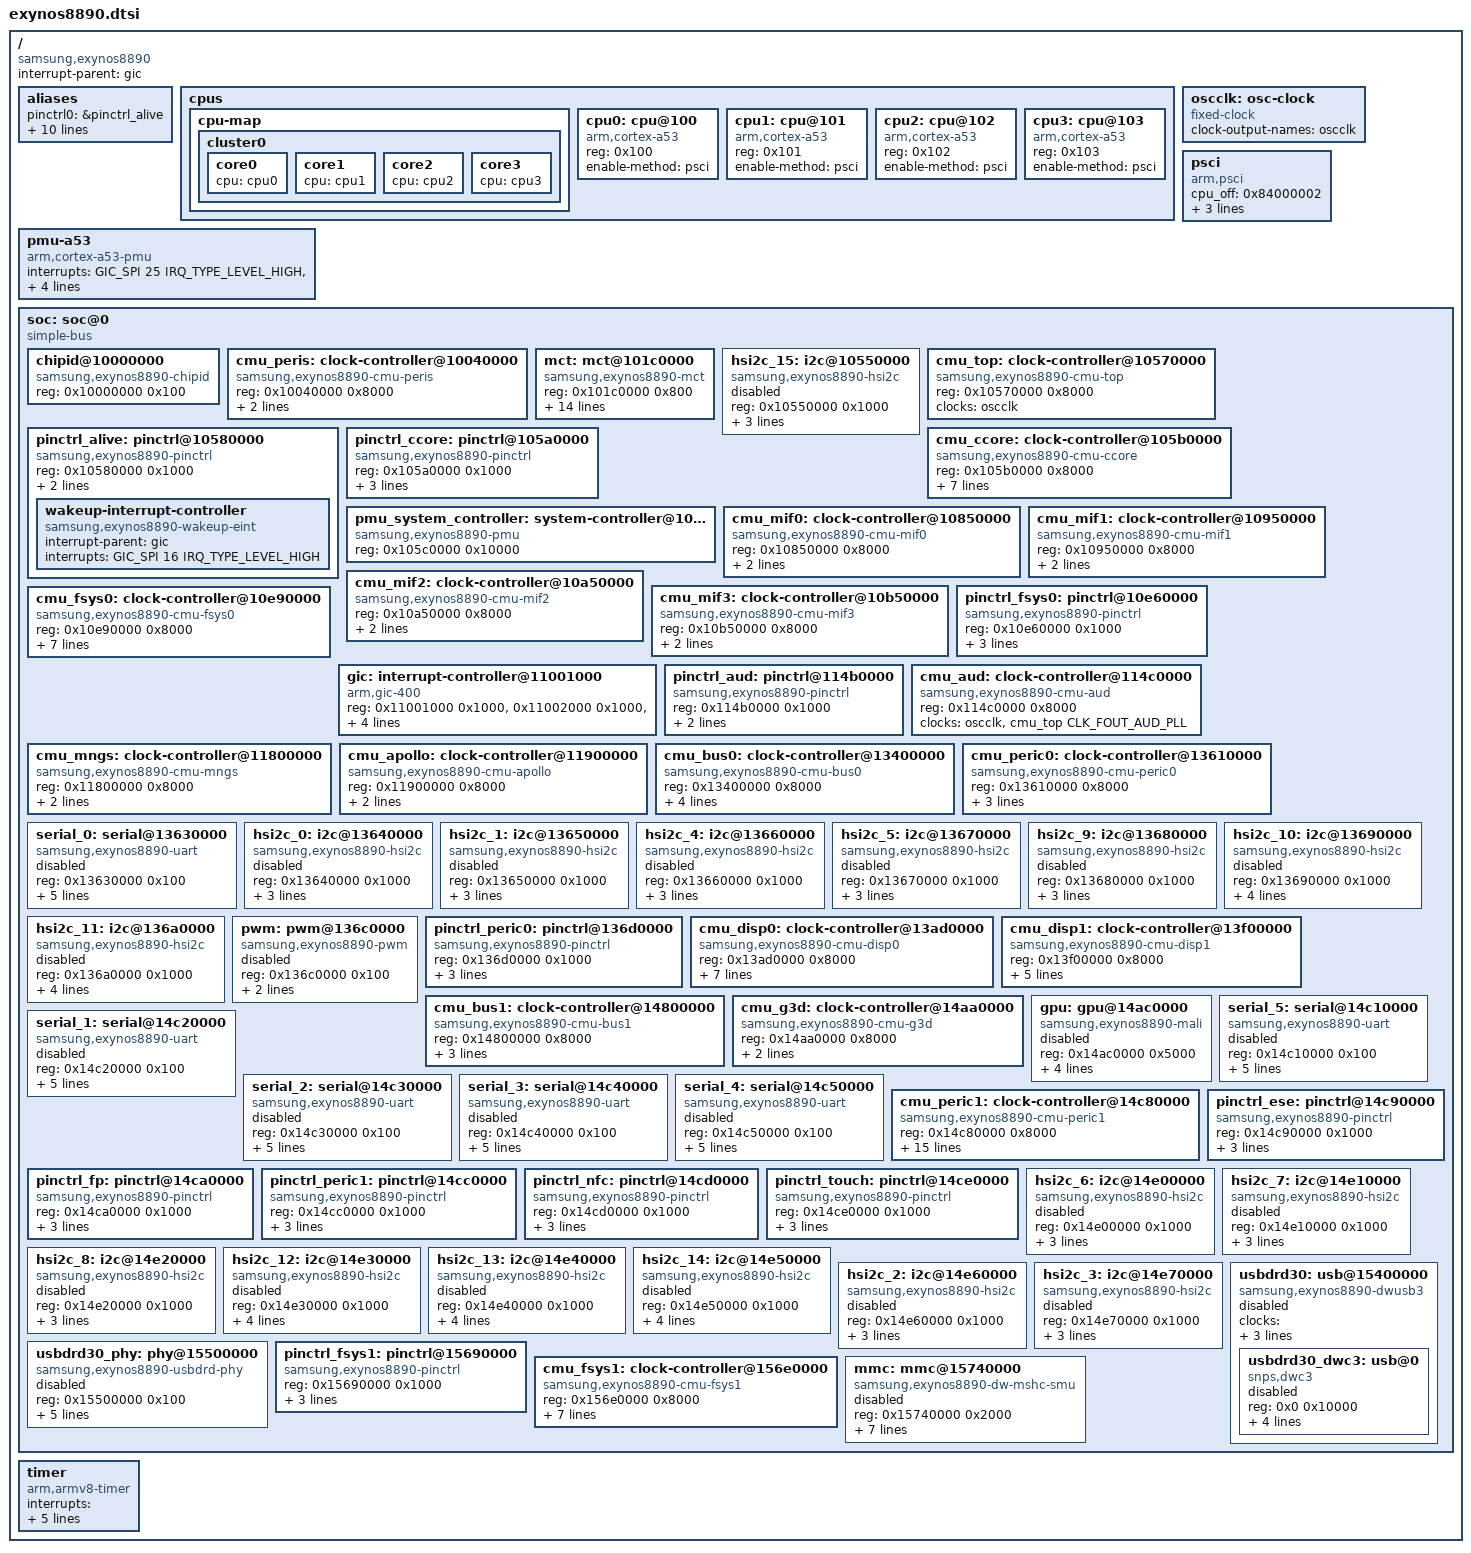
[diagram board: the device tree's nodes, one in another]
// SPDX-License-Identifier: GPL-2.0 OR BSD-3-Clause
/*
 * Samsung Exynos 8890 SoC device tree source
 *
 * Copyright (c) 2025 Ivaylo Ivanov <ivo.ivanov.ivanov1@gmail.com>
 */

#include <dt-bindings/clock/samsung,exynos8890-cmu.h>
#include <dt-bindings/interrupt-controller/arm-gic.h>

/ {
	compatible = "samsung,exynos8890";
	#address-cells = <2>;
	#size-cells = <1>;

	interrupt-parent = <&gic>;

	aliases {
		pinctrl0 = &pinctrl_alive;
		pinctrl1 = &pinctrl_aud;
		pinctrl2 = &pinctrl_ccore;
		pinctrl3 = &pinctrl_fp;
		pinctrl4 = &pinctrl_ese;
		pinctrl5 = &pinctrl_fsys0;
		pinctrl6 = &pinctrl_fsys1;
		pinctrl7 = &pinctrl_nfc;
		pinctrl8 = &pinctrl_peric0;
		pinctrl9 = &pinctrl_peric1;
		pinctrl10 = &pinctrl_touch;
	};

	cpus {
		#address-cells = <1>;
		#size-cells = <0>;

		cpu-map {
			cluster0 {
				core0 {
					cpu = <&cpu0>;
				};
				core1 {
					cpu = <&cpu1>;
				};
				core2 {
					cpu = <&cpu2>;
				};
				core3 {
					cpu = <&cpu3>;
				};
			};
		};

		/*
		 * The Mongoose M1 cores have an errata, where memory accesses
		 * to certain virtual addresses can trigger a TLB conflict abort,
		 * even when running Linux in EL2.
		 */

		cpu0: cpu@100 {
			device_type = "cpu";
			compatible = "arm,cortex-a53";
			reg = <0x100>;
			enable-method = "psci";
		};

		cpu1: cpu@101 {
			device_type = "cpu";
			compatible = "arm,cortex-a53";
			reg = <0x101>;
			enable-method = "psci";
		};

		cpu2: cpu@102 {
			device_type = "cpu";
			compatible = "arm,cortex-a53";
			reg = <0x102>;
			enable-method = "psci";
		};

		cpu3: cpu@103 {
			device_type = "cpu";
			compatible = "arm,cortex-a53";
			reg = <0x103>;
			enable-method = "psci";
		};
	};

	oscclk: osc-clock {
		compatible = "fixed-clock";
		#clock-cells = <0>;
		clock-output-names = "oscclk";
	};

	pmu-a53 {
		compatible = "arm,cortex-a53-pmu";
		interrupts = <GIC_SPI 25 IRQ_TYPE_LEVEL_HIGH>,
			     <GIC_SPI 26 IRQ_TYPE_LEVEL_HIGH>,
			     <GIC_SPI 27 IRQ_TYPE_LEVEL_HIGH>,
			     <GIC_SPI 28 IRQ_TYPE_LEVEL_HIGH>;
		interrupt-affinity = <&cpu0>,
				     <&cpu1>,
				     <&cpu2>,
				     <&cpu3>;
	};

	psci {
		compatible = "arm,psci";
		cpu_off = <0x84000002>;
		cpu_on = <0xc4000003>;
		cpu_suspend = <0xc4000001>;
		method = "smc";
	};

	soc: soc@0 {
		compatible = "simple-bus";
		ranges = <0x0 0x0 0x0 0x20000000>;

		#address-cells = <1>;
		#size-cells = <1>;

		chipid@10000000 {
			compatible = "samsung,exynos8890-chipid",
				     "samsung,exynos4210-chipid";
			reg = <0x10000000 0x100>;
		};

		cmu_peris: clock-controller@10040000 {
			compatible = "samsung,exynos8890-cmu-peris";
			reg = <0x10040000 0x8000>;
			#clock-cells = <1>;
			clocks = <&oscclk>,
				 <&cmu_top CLK_GOUT_TOP_ACLK_PERIS_66>;
			clock-names = "oscclk", "peris";
		};

		mct: mct@101c0000 {
			compatible = "samsung,exynos8890-mct",
				     "samsung,exynos4210-mct";
			reg = <0x101c0000 0x800>;

			clocks = <&oscclk>, <&cmu_peris CLK_GOUT_PERIS_PCLK_MCT>;
			clock-names = "fin_pll", "mct";

			interrupts = <GIC_SPI 81 IRQ_TYPE_LEVEL_HIGH>,
				     <GIC_SPI 82 IRQ_TYPE_LEVEL_HIGH>,
				     <GIC_SPI 83 IRQ_TYPE_LEVEL_HIGH>,
				     <GIC_SPI 84 IRQ_TYPE_LEVEL_HIGH>,
				     <GIC_SPI 85 IRQ_TYPE_LEVEL_HIGH>,
				     <GIC_SPI 86 IRQ_TYPE_LEVEL_HIGH>,
				     <GIC_SPI 87 IRQ_TYPE_LEVEL_HIGH>,
				     <GIC_SPI 88 IRQ_TYPE_LEVEL_HIGH>,
				     <GIC_SPI 89 IRQ_TYPE_LEVEL_HIGH>,
				     <GIC_SPI 90 IRQ_TYPE_LEVEL_HIGH>,
				     <GIC_SPI 91 IRQ_TYPE_LEVEL_HIGH>,
				     <GIC_SPI 92 IRQ_TYPE_LEVEL_HIGH>;
		};

		hsi2c_15: i2c@10550000 {
			compatible = "samsung,exynos8890-hsi2c",
				     "samsung,exynos8895-hsi2c";
			reg = <0x10550000 0x1000>;

			clocks = <&cmu_ccore CLK_GOUT_CCORE_PCLK_HSI2C>;
			clock-names = "hsi2c";

			interrupts = <GIC_SPI 340 IRQ_TYPE_LEVEL_HIGH>;

			pinctrl-0 = <&hsi2c15_bus>;
			pinctrl-names = "default";

			#address-cells = <1>;
			#size-cells = <0>;

			status = "disabled";
		};

		cmu_top: clock-controller@10570000 {
			compatible = "samsung,exynos8890-cmu-top";
			reg = <0x10570000 0x8000>;
			#clock-cells = <1>;
			clocks = <&oscclk>;
			clock-names = "oscclk";
		};

		pinctrl_alive: pinctrl@10580000 {
			compatible = "samsung,exynos8890-pinctrl";
			reg = <0x10580000 0x1000>;
			clocks = <&cmu_ccore CLK_GOUT_CCORE_PCLK_GPIO_APBIF_ALIVE>;
			clock-names = "pclk";

			wakeup-interrupt-controller {
				compatible = "samsung,exynos8890-wakeup-eint",
					     "samsung,exynos7-wakeup-eint";
				interrupt-parent = <&gic>;
				interrupts = <GIC_SPI 16 IRQ_TYPE_LEVEL_HIGH>;
			};
		};

		pinctrl_ccore: pinctrl@105a0000 {
			compatible = "samsung,exynos8890-pinctrl";
			reg = <0x105a0000 0x1000>;
			interrupts = <GIC_SPI 383 IRQ_TYPE_LEVEL_HIGH>;
			clocks = <&cmu_ccore CLK_GOUT_CCORE_PCLK_GPIO_CCORE>;
			clock-names = "pclk";
		};

		cmu_ccore: clock-controller@105b0000 {
			compatible = "samsung,exynos8890-cmu-ccore";
			reg = <0x105b0000 0x8000>;
			#clock-cells = <1>;
			clocks = <&oscclk>,
				 <&cmu_top CLK_GOUT_TOP_ACLK_CCORE_800>,
				 <&cmu_top CLK_GOUT_TOP_ACLK_CCORE_264>,
				 <&cmu_top CLK_GOUT_TOP_ACLK_CCORE_G3D_800>,
				 <&cmu_top CLK_GOUT_TOP_ACLK_CCORE_528>,
				 <&cmu_top CLK_GOUT_TOP_ACLK_CCORE_132>,
				 <&cmu_top CLK_GOUT_TOP_PCLK_CCORE_66>;
			clock-names = "oscclk", "800", "264", "g3d", "528",
				      "132", "66";
		};

		pmu_system_controller: system-controller@105c0000 {
			compatible = "samsung,exynos8890-pmu",
				     "samsung,exynos7-pmu", "syscon";
			reg = <0x105c0000 0x10000>;
		};

		cmu_mif0: clock-controller@10850000 {
			compatible = "samsung,exynos8890-cmu-mif0";
			reg = <0x10850000 0x8000>;
			#clock-cells = <1>;
			clocks = <&oscclk>,
				 <&cmu_top CLK_GOUT_TOP_SCLK_BUS_PLL_MIF>;
			clock-names = "oscclk", "bus";
		};

		cmu_mif1: clock-controller@10950000 {
			compatible = "samsung,exynos8890-cmu-mif1";
			reg = <0x10950000 0x8000>;
			#clock-cells = <1>;
			clocks = <&oscclk>,
				 <&cmu_top CLK_GOUT_TOP_SCLK_BUS_PLL_MIF>;
			clock-names = "oscclk", "bus";
		};

		cmu_mif2: clock-controller@10a50000 {
			compatible = "samsung,exynos8890-cmu-mif2";
			reg = <0x10a50000 0x8000>;
			#clock-cells = <1>;
			clocks = <&oscclk>,
				 <&cmu_top CLK_GOUT_TOP_SCLK_BUS_PLL_MIF>;
			clock-names = "oscclk", "bus";
		};

		cmu_mif3: clock-controller@10b50000 {
			compatible = "samsung,exynos8890-cmu-mif3";
			reg = <0x10b50000 0x8000>;
			#clock-cells = <1>;
			clocks = <&oscclk>,
				 <&cmu_top CLK_GOUT_TOP_SCLK_BUS_PLL_MIF>;
			clock-names = "oscclk", "bus";
		};

		pinctrl_fsys0: pinctrl@10e60000 {
			compatible = "samsung,exynos8890-pinctrl";
			reg = <0x10e60000 0x1000>;
			clocks = <&cmu_fsys0 CLK_GOUT_FSYS0_PCLK_GPIO_FSYS0>;
			clock-names = "pclk";
			interrupts = <GIC_SPI 212 IRQ_TYPE_LEVEL_HIGH>;
		};

		cmu_fsys0: clock-controller@10e90000 {
			compatible = "samsung,exynos8890-cmu-fsys0";
			reg = <0x10e90000 0x8000>;
			#clock-cells = <1>;
			clocks = <&oscclk>,
				 <&cmu_top CLK_GOUT_TOP_ACLK_FSYS0_200>,
				 <&cmu_top CLK_GOUT_TOP_SCLK_FSYS0_USBDRD30>,
				 <&cmu_top CLK_GOUT_TOP_SCLK_FSYS0_MMC0>,
				 <&cmu_top CLK_GOUT_TOP_SCLK_FSYS0_UFSUNIPRO20>,
				 <&cmu_top CLK_GOUT_TOP_SCLK_FSYS0_PHY_24M>,
				 <&cmu_top CLK_GOUT_TOP_SCLK_FSYS0_UFSUNIPRO_CFG>;
			clock-names = "oscclk", "200", "usb", "mmc", "unipro20",
				      "24m", "unipro_cfg";
		};

		gic: interrupt-controller@11001000 {
			compatible = "arm,gic-400";
			reg = <0x11001000 0x1000>,
			      <0x11002000 0x1000>,
			      <0x11004000 0x2000>,
			      <0x11006000 0x2000>;
			#interrupt-cells = <3>;
			interrupt-controller;
			interrupts = <GIC_PPI 9 (GIC_CPU_MASK_SIMPLE(8) |
						 IRQ_TYPE_LEVEL_HIGH)>;
			#address-cells = <0>;
			#size-cells = <1>;
		};

		pinctrl_aud: pinctrl@114b0000 {
			compatible = "samsung,exynos8890-pinctrl";
			reg = <0x114b0000 0x1000>;
			clocks = <&cmu_aud CLK_GOUT_AUD_PCLK_GPIO_AUD>;
			clock-names = "pclk";
			interrupts = <GIC_SPI 61 IRQ_TYPE_LEVEL_HIGH>;
		};

		cmu_aud: clock-controller@114c0000 {
			compatible = "samsung,exynos8890-cmu-aud";
			reg = <0x114c0000 0x8000>;
			#clock-cells = <1>;
			clocks = <&oscclk>,
				 <&cmu_top CLK_FOUT_AUD_PLL>;
			clock-names = "oscclk", "pll";
		};

		cmu_mngs: clock-controller@11800000 {
			compatible = "samsung,exynos8890-cmu-mngs";
			reg = <0x11800000 0x8000>;
			#clock-cells = <1>;
			clocks = <&oscclk>,
				 <&cmu_top CLK_GOUT_TOP_SCLK_BUS_PLL_MNGS>;
			clock-names = "oscclk", "bus";
		};

		cmu_apollo: clock-controller@11900000 {
			compatible = "samsung,exynos8890-cmu-apollo";
			reg = <0x11900000 0x8000>;
			#clock-cells = <1>;
			clocks = <&oscclk>,
				 <&cmu_top CLK_GOUT_TOP_SCLK_BUS_PLL_APOLLO>;
			clock-names = "oscclk", "bus";
		};

		cmu_bus0: clock-controller@13400000 {
			compatible = "samsung,exynos8890-cmu-bus0";
			reg = <0x13400000 0x8000>;
			#clock-cells = <1>;
			clocks = <&oscclk>,
				 <&cmu_top CLK_GOUT_TOP_ACLK_BUS0_528>,
				 <&cmu_top CLK_GOUT_TOP_ACLK_BUS0_200>,
				 <&cmu_top CLK_GOUT_TOP_PCLK_BUS0_132>;
			clock-names = "oscclk", "528", "200", "132";
		};

		cmu_peric0: clock-controller@13610000 {
			compatible = "samsung,exynos8890-cmu-peric0";
			reg = <0x13610000 0x8000>;
			#clock-cells = <1>;
			clocks = <&oscclk>,
				 <&cmu_top CLK_GOUT_TOP_ACLK_PERIC0_66>,
				 <&cmu_top CLK_GOUT_TOP_SCLK_PERIC0_UART0>;
			clock-names = "oscclk", "66", "uart0";
		};

		serial_0: serial@13630000 {
			compatible = "samsung,exynos8890-uart",
				     "samsung,exynos8895-uart";
			reg = <0x13630000 0x100>;

			clocks = <&cmu_peric0 CLK_GOUT_PERIC0_PCLK_UART0>,
				 <&cmu_peric0 CLK_GOUT_PERIC0_SCLK_UART0>;
			clock-names = "uart", "clk_uart_baud0";

			interrupts = <GIC_SPI 429 IRQ_TYPE_LEVEL_HIGH>;

			pinctrl-0 = <&uart0_bus>;
			pinctrl-names = "default";

			samsung,uart-fifosize = <256>;

			status = "disabled";
		};

		hsi2c_0: i2c@13640000 {
			compatible = "samsung,exynos8890-hsi2c",
				     "samsung,exynos8895-hsi2c";
			reg = <0x13640000 0x1000>;

			clocks = <&cmu_peric0 CLK_GOUT_PERIC0_PCLK_HSI2C0>;
			clock-names = "hsi2c";

			interrupts = <GIC_SPI 416 IRQ_TYPE_LEVEL_HIGH>;

			pinctrl-0 = <&hsi2c0_bus>;
			pinctrl-names = "default";

			#address-cells = <1>;
			#size-cells = <0>;

			status = "disabled";
		};

		hsi2c_1: i2c@13650000 {
			compatible = "samsung,exynos8890-hsi2c",
				     "samsung,exynos8895-hsi2c";
			reg = <0x13650000 0x1000>;

			clocks = <&cmu_peric0 CLK_GOUT_PERIC0_PCLK_HSI2C1>;
			clock-names = "hsi2c";

			interrupts = <GIC_SPI 417 IRQ_TYPE_LEVEL_HIGH>;

			pinctrl-0 = <&hsi2c1_bus>;
			pinctrl-names = "default";

			#address-cells = <1>;
			#size-cells = <0>;

			status = "disabled";
		};

		hsi2c_4: i2c@13660000 {
			compatible = "samsung,exynos8890-hsi2c",
				     "samsung,exynos8895-hsi2c";
			reg = <0x13660000 0x1000>;

			clocks = <&cmu_peric0 CLK_GOUT_PERIC0_PCLK_HSI2C4>;
			clock-names = "hsi2c";

			interrupts = <GIC_SPI 418 IRQ_TYPE_LEVEL_HIGH>;

			pinctrl-0 = <&hsi2c4_bus>;
			pinctrl-names = "default";

			#address-cells = <1>;
			#size-cells = <0>;

			status = "disabled";
		};

		hsi2c_5: i2c@13670000 {
			compatible = "samsung,exynos8890-hsi2c",
				     "samsung,exynos8895-hsi2c";
			reg = <0x13670000 0x1000>;

			clocks = <&cmu_peric0 CLK_GOUT_PERIC0_PCLK_HSI2C5>;
			clock-names = "hsi2c";

			interrupts = <GIC_SPI 419 IRQ_TYPE_LEVEL_HIGH>;

			pinctrl-0 = <&hsi2c5_bus>;
			pinctrl-names = "default";

			#address-cells = <1>;
			#size-cells = <0>;

			status = "disabled";
		};

		hsi2c_9: i2c@13680000 {
			compatible = "samsung,exynos8890-hsi2c",
				     "samsung,exynos8895-hsi2c";
			reg = <0x13680000 0x1000>;

			clocks = <&cmu_peric0 CLK_GOUT_PERIC0_PCLK_HSI2C9>;
			clock-names = "hsi2c";

			interrupts = <GIC_SPI 420 IRQ_TYPE_LEVEL_HIGH>;

			pinctrl-0 = <&hsi2c9_bus>;
			pinctrl-names = "default";

			#address-cells = <1>;
			#size-cells = <0>;

			status = "disabled";
		};

		hsi2c_10: i2c@13690000 {
			compatible = "samsung,exynos8890-hsi2c",
				     "samsung,exynos8895-hsi2c";
			reg = <0x13690000 0x1000>;

			clocks = <&cmu_peric0 CLK_GOUT_PERIC0_PCLK_HSI2C10>;
			clock-names = "hsi2c";

			interrupts = <GIC_SPI 421 IRQ_TYPE_LEVEL_HIGH>;

			pinctrl-0 = <&hsi2c10_bus>;
			pinctrl-names = "default";

			#address-cells = <1>;
			#size-cells = <0>;

			status = "disabled";
		};

		hsi2c_11: i2c@136a0000 {
			compatible = "samsung,exynos8890-hsi2c",
				     "samsung,exynos8895-hsi2c";
			reg = <0x136a0000 0x1000>;

			clocks = <&cmu_peric0 CLK_GOUT_PERIC0_PCLK_HSI2C11>;
			clock-names = "hsi2c";

			interrupts = <GIC_SPI 422 IRQ_TYPE_LEVEL_HIGH>;

			pinctrl-0 = <&hsi2c11_bus>;
			pinctrl-names = "default";

			#address-cells = <1>;
			#size-cells = <0>;

			status = "disabled";
		};

		pwm: pwm@136c0000 {
			compatible = "samsung,exynos8890-pwm",
				     "samsung,exynos4210-pwm";
			reg = <0x136c0000 0x100>;
			clocks = <&cmu_peric0 CLK_GOUT_PERIC0_PCLK_PWM>;
			clock-names = "timers";
			#pwm-cells = <3>;
			samsung,pwm-outputs = <0>, <1>, <2>, <3>;
			status = "disabled";
		};

		pinctrl_peric0: pinctrl@136d0000 {
			compatible = "samsung,exynos8890-pinctrl";
			reg = <0x136d0000 0x1000>;
			interrupts = <GIC_SPI 430 IRQ_TYPE_LEVEL_HIGH>;
			clocks = <&cmu_peric0 CLK_GOUT_PERIC0_PCLK_GPIO_BUS0>;
			clock-names = "pclk";
		};

		cmu_disp0: clock-controller@13ad0000 {
			compatible = "samsung,exynos8890-cmu-disp0";
			reg = <0x13ad0000 0x8000>;
			#clock-cells = <1>;
			clocks = <&oscclk>,
				 <&cmu_top CLK_GOUT_TOP_ACLK_DISP0_0_400>,
				 <&cmu_top CLK_GOUT_TOP_ACLK_DISP0_1_400>,
				 <&cmu_top CLK_GOUT_TOP_SCLK_DISP0_DECON0_ECLK0>,
				 <&cmu_top CLK_GOUT_TOP_SCLK_DISP0_DECON0_VCLK0>,
				 <&cmu_top CLK_GOUT_TOP_SCLK_DISP0_DECON0_VCLK1>,
				 <&cmu_top CLK_GOUT_TOP_SCLK_DISP0_HDMI_AUDIO>;
			clock-names = "oscclk", "0_400", "1_400", "eclk0",
				      "vclk0", "vclk1", "audio";
		};

		cmu_disp1: clock-controller@13f00000 {
			compatible = "samsung,exynos8890-cmu-disp1";
			reg = <0x13f00000 0x8000>;
			#clock-cells = <1>;
			clocks = <&oscclk>,
				 <&cmu_top CLK_GOUT_TOP_ACLK_DISP1_0_400>,
				 <&cmu_top CLK_GOUT_TOP_ACLK_DISP1_1_400>,
				 <&cmu_top CLK_GOUT_TOP_SCLK_DISP1_DECON1_ECLK0>,
				 <&cmu_top CLK_GOUT_TOP_SCLK_DISP1_DECON1_ECLK1>;
			clock-names = "oscclk", "0_400", "1_400", "eclk0",
				      "eclk01";
		};

		cmu_bus1: clock-controller@14800000 {
			compatible = "samsung,exynos8890-cmu-bus1";
			reg = <0x14800000 0x8000>;
			#clock-cells = <1>;
			clocks = <&oscclk>,
				 <&cmu_top CLK_GOUT_TOP_ACLK_BUS0_528>,
				 <&cmu_top CLK_GOUT_TOP_PCLK_BUS1_132>;
			clock-names = "oscclk", "528", "132";
		};

		cmu_g3d: clock-controller@14aa0000 {
			compatible = "samsung,exynos8890-cmu-g3d";
			reg = <0x14aa0000 0x8000>;
			#clock-cells = <1>;
			clocks = <&oscclk>,
				 <&cmu_top CLK_FOUT_G3D_PLL>,
				 <&cmu_top CLK_GOUT_TOP_SCLK_BUS_PLL_G3D>;
			clock-names = "oscclk", "pll", "bus";
		};

		gpu: gpu@14ac0000 {
			compatible = "samsung,exynos8890-mali", "arm,mali-t880";
			reg = <0x14ac0000 0x5000>;

			clocks = <&cmu_g3d CLK_GOUT_G3D_ACLK_G3D>;
			clock-names = "core";

			interrupts = <GIC_SPI 225 IRQ_TYPE_LEVEL_HIGH>,
				     <GIC_SPI 226 IRQ_TYPE_LEVEL_HIGH>,
				     <GIC_SPI 224 IRQ_TYPE_LEVEL_HIGH>;
			interrupt-names = "job", "mmu", "gpu";

			status = "disabled";
		};

		serial_5: serial@14c10000 {
			compatible = "samsung,exynos8890-uart",
				     "samsung,exynos8895-uart";
			reg = <0x14c10000 0x100>;

			clocks = <&cmu_peric1 CLK_GOUT_PERIC1_PCLK_UART5>,
				 <&cmu_peric1 CLK_GOUT_PERIC1_SCLK_UART5>;
			clock-names = "uart", "clk_uart_baud0";

			interrupts = <GIC_SPI 436 IRQ_TYPE_LEVEL_HIGH>;

			pinctrl-0 = <&uart5_bus>;
			pinctrl-names = "default";

			samsung,uart-fifosize = <64>;

			status = "disabled";
		};

		serial_1: serial@14c20000 {
			compatible = "samsung,exynos8890-uart",
				     "samsung,exynos8895-uart";
			reg = <0x14c20000 0x100>;

			clocks = <&cmu_peric1 CLK_GOUT_PERIC1_PCLK_UART1>,
				 <&cmu_peric1 CLK_GOUT_PERIC1_SCLK_UART1>;
			clock-names = "uart", "clk_uart_baud0";

			interrupts = <GIC_SPI 432 IRQ_TYPE_LEVEL_HIGH>;

			pinctrl-0 = <&uart1_bus>;
			pinctrl-names = "default";

			samsung,uart-fifosize = <256>;

			status = "disabled";
		};

		serial_2: serial@14c30000 {
			compatible = "samsung,exynos8890-uart",
				     "samsung,exynos8895-uart";
			reg = <0x14c30000 0x100>;

			clocks = <&cmu_peric1 CLK_GOUT_PERIC1_PCLK_UART2>,
				 <&cmu_peric1 CLK_GOUT_PERIC1_SCLK_UART2>;
			clock-names = "uart", "clk_uart_baud0";

			interrupts = <GIC_SPI 433 IRQ_TYPE_LEVEL_HIGH>;

			pinctrl-0 = <&uart2_bus>;
			pinctrl-names = "default";

			samsung,uart-fifosize = <16>;

			status = "disabled";
		};

		serial_3: serial@14c40000 {
			compatible = "samsung,exynos8890-uart",
				     "samsung,exynos8895-uart";
			reg = <0x14c40000 0x100>;

			clocks = <&cmu_peric1 CLK_GOUT_PERIC1_PCLK_UART3>,
				 <&cmu_peric1 CLK_GOUT_PERIC1_SCLK_UART3>;
			clock-names = "uart", "clk_uart_baud0";

			interrupts = <GIC_SPI 434 IRQ_TYPE_LEVEL_HIGH>;

			pinctrl-0 = <&uart3_bus>;
			pinctrl-names = "default";

			samsung,uart-fifosize = <64>;

			status = "disabled";
		};

		serial_4: serial@14c50000 {
			compatible = "samsung,exynos8890-uart",
				     "samsung,exynos8895-uart";
			reg = <0x14c50000 0x100>;

			clocks = <&cmu_peric1 CLK_GOUT_PERIC1_PCLK_UART4>,
				 <&cmu_peric1 CLK_GOUT_PERIC1_SCLK_UART4>;
			clock-names = "uart", "clk_uart_baud0";

			interrupts = <GIC_SPI 435 IRQ_TYPE_LEVEL_HIGH>;

			pinctrl-0 = <&uart4_bus>;
			pinctrl-names = "default";

			samsung,uart-fifosize = <256>;

			status = "disabled";
		};

		cmu_peric1: clock-controller@14c80000 {
			compatible = "samsung,exynos8890-cmu-peric1";
			reg = <0x14c80000 0x8000>;
			#clock-cells = <1>;
			clocks = <&oscclk>,
				 <&cmu_top CLK_GOUT_TOP_ACLK_PERIC1_66>,
				 <&cmu_top CLK_GOUT_TOP_SCLK_PERIC1_SPI0>,
				 <&cmu_top CLK_GOUT_TOP_SCLK_PERIC1_SPI1>,
				 <&cmu_top CLK_GOUT_TOP_SCLK_PERIC1_SPI2>,
				 <&cmu_top CLK_GOUT_TOP_SCLK_PERIC1_SPI3>,
				 <&cmu_top CLK_GOUT_TOP_SCLK_PERIC1_SPI4>,
				 <&cmu_top CLK_GOUT_TOP_SCLK_PERIC1_SPI5>,
				 <&cmu_top CLK_GOUT_TOP_SCLK_PERIC1_SPI6>,
				 <&cmu_top CLK_GOUT_TOP_SCLK_PERIC1_SPI7>,
				 <&cmu_top CLK_GOUT_TOP_SCLK_PERIC1_UART1>,
				 <&cmu_top CLK_GOUT_TOP_SCLK_PERIC1_UART2>,
				 <&cmu_top CLK_GOUT_TOP_SCLK_PERIC1_UART3>,
				 <&cmu_top CLK_GOUT_TOP_SCLK_PERIC1_UART4>,
				 <&cmu_top CLK_GOUT_TOP_SCLK_PERIC1_UART5>;
			clock-names = "oscclk", "66", "spi0", "spi1",
				      "spi2", "spi3", "spi4", "spi5", "spi6",
				      "spi7", "uart1", "uart2", "uart3",
				      "uart4", "uart5";
		};

		pinctrl_ese: pinctrl@14c90000 {
			compatible = "samsung,exynos8890-pinctrl";
			reg = <0x14c90000 0x1000>;
			clocks = <&cmu_peric1 CLK_GOUT_PERIC1_PCLK_GPIO_ESE>;
			clock-names = "pclk";
			interrupts = <GIC_SPI 458 IRQ_TYPE_LEVEL_HIGH>;
		};

		pinctrl_fp: pinctrl@14ca0000 {
			compatible = "samsung,exynos8890-pinctrl";
			reg = <0x14ca0000 0x1000>;
			clocks = <&cmu_peric1 CLK_GOUT_PERIC1_PCLK_GPIO_FF>;
			clock-names = "pclk";
			interrupts = <GIC_SPI 459 IRQ_TYPE_LEVEL_HIGH>;
		};

		pinctrl_peric1: pinctrl@14cc0000 {
			compatible = "samsung,exynos8890-pinctrl";
			reg = <0x14cc0000 0x1000>;
			clocks = <&cmu_peric1 CLK_GOUT_PERIC1_PCLK_GPIO_PERIC1>;
			clock-names = "pclk";
			interrupts = <GIC_SPI 460 IRQ_TYPE_LEVEL_HIGH>;
		};

		pinctrl_nfc: pinctrl@14cd0000 {
			compatible = "samsung,exynos8890-pinctrl";
			reg = <0x14cd0000 0x1000>;
			clocks = <&cmu_peric1 CLK_GOUT_PERIC1_PCLK_GPIO_NFC>;
			clock-names = "pclk";
			interrupts = <GIC_SPI 456 IRQ_TYPE_LEVEL_HIGH>;
		};

		pinctrl_touch: pinctrl@14ce0000 {
			compatible = "samsung,exynos8890-pinctrl";
			reg = <0x14ce0000 0x1000>;
			clocks = <&cmu_peric1 CLK_GOUT_PERIC1_PCLK_GPIO_TOUCH>;
			clock-names = "pclk";
			interrupts = <GIC_SPI 457 IRQ_TYPE_LEVEL_HIGH>;
		};

		hsi2c_6: i2c@14e00000 {
			compatible = "samsung,exynos8890-hsi2c",
				     "samsung,exynos8895-hsi2c";
			reg = <0x14e00000 0x1000>;

			clocks = <&cmu_peric1 CLK_GOUT_PERIC1_PCLK_HSI2C6>;
			clock-names = "hsi2c";

			interrupts = <GIC_SPI 439 IRQ_TYPE_LEVEL_HIGH>;

			pinctrl-0 = <&hsi2c6_bus>;
			pinctrl-names = "default";

			#address-cells = <1>;
			#size-cells = <0>;

			status = "disabled";
		};

		hsi2c_7: i2c@14e10000 {
			compatible = "samsung,exynos8890-hsi2c",
				     "samsung,exynos8895-hsi2c";
			reg = <0x14e10000 0x1000>;

			clocks = <&cmu_peric1 CLK_GOUT_PERIC1_PCLK_HSI2C7>;
			clock-names = "hsi2c";

			interrupts = <GIC_SPI 440 IRQ_TYPE_LEVEL_HIGH>;

			pinctrl-0 = <&hsi2c7_bus>;
			pinctrl-names = "default";

			#address-cells = <1>;
			#size-cells = <0>;

			status = "disabled";
		};

		hsi2c_8: i2c@14e20000 {
			compatible = "samsung,exynos8890-hsi2c",
				     "samsung,exynos8895-hsi2c";
			reg = <0x14e20000 0x1000>;

			clocks = <&cmu_peric1 CLK_GOUT_PERIC1_PCLK_HSI2C8>;
			clock-names = "hsi2c";

			interrupts = <GIC_SPI 441 IRQ_TYPE_LEVEL_HIGH>;

			pinctrl-0 = <&hsi2c8_bus>;
			pinctrl-names = "default";

			#address-cells = <1>;
			#size-cells = <0>;

			status = "disabled";
		};

		hsi2c_12: i2c@14e30000 {
			compatible = "samsung,exynos8890-hsi2c",
				     "samsung,exynos8895-hsi2c";
			reg = <0x14e30000 0x1000>;

			clocks = <&cmu_peric1 CLK_GOUT_PERIC1_PCLK_HSI2C12>;
			clock-names = "hsi2c";

			interrupts = <GIC_SPI 442 IRQ_TYPE_LEVEL_HIGH>;

			pinctrl-0 = <&hsi2c12_bus>;
			pinctrl-names = "default";

			#address-cells = <1>;
			#size-cells = <0>;

			status = "disabled";
		};

		hsi2c_13: i2c@14e40000 {
			compatible = "samsung,exynos8890-hsi2c",
				     "samsung,exynos8895-hsi2c";
			reg = <0x14e40000 0x1000>;

			clocks = <&cmu_peric1 CLK_GOUT_PERIC1_PCLK_HSI2C13>;
			clock-names = "hsi2c";

			interrupts = <GIC_SPI 443 IRQ_TYPE_LEVEL_HIGH>;

			pinctrl-0 = <&hsi2c13_bus>;
			pinctrl-names = "default";

			#address-cells = <1>;
			#size-cells = <0>;

			status = "disabled";
		};

		hsi2c_14: i2c@14e50000 {
			compatible = "samsung,exynos8890-hsi2c",
				     "samsung,exynos8895-hsi2c";
			reg = <0x14e50000 0x1000>;

			clocks = <&cmu_peric1 CLK_GOUT_PERIC1_PCLK_HSI2C14>;
			clock-names = "hsi2c";

			interrupts = <GIC_SPI 444 IRQ_TYPE_LEVEL_HIGH>;

			pinctrl-0 = <&hsi2c14_bus>;
			pinctrl-names = "default";

			#address-cells = <1>;
			#size-cells = <0>;

			status = "disabled";
		};

		hsi2c_2: i2c@14e60000 {
			compatible = "samsung,exynos8890-hsi2c",
				     "samsung,exynos8895-hsi2c";
			reg = <0x14e60000 0x1000>;

			clocks = <&cmu_peric1 CLK_GOUT_PERIC1_PCLK_HSI2C2>;
			clock-names = "hsi2c";

			interrupts = <GIC_SPI 437 IRQ_TYPE_LEVEL_HIGH>;

			pinctrl-0 = <&hsi2c2_bus>;
			pinctrl-names = "default";

			#address-cells = <1>;
			#size-cells = <0>;

			status = "disabled";
		};

		hsi2c_3: i2c@14e70000 {
			compatible = "samsung,exynos8890-hsi2c",
				     "samsung,exynos8895-hsi2c";
			reg = <0x14e70000 0x1000>;

			clocks = <&cmu_peric1 CLK_GOUT_PERIC1_PCLK_HSI2C3>;
			clock-names = "hsi2c";

			interrupts = <GIC_SPI 438 IRQ_TYPE_LEVEL_HIGH>;

			pinctrl-0 = <&hsi2c3_bus>;
			pinctrl-names = "default";

			#address-cells = <1>;
			#size-cells = <0>;

			status = "disabled";
		};

		usbdrd30: usb@15400000 {
			compatible = "samsung,exynos8890-dwusb3",
				     "samsung,exynos7-dwusb3";
			ranges = <0x0 0x15400000 0x10000>;

			clocks = <&cmu_fsys0 CLK_GOUT_FSYS0_ACLK_USBDRD30>,
				 <&cmu_fsys0 CLK_GOUT_FSYS0_SCLK_USBDRD30_SUSPEND_CLK>,
				 <&cmu_fsys0 CLK_GOUT_FSYS0_ACLK_AXI_US_USBDRD30X_FSYS0X>;
			clock-names = "usbdrd30", "usbdrd30_susp_clk",
				      "usbdrd30_axius_clk";

			#address-cells = <1>;
			#size-cells = <1>;

			status = "disabled";

			usbdrd30_dwc3: usb@0 {
				compatible = "snps,dwc3";
				reg = <0x0 0x10000>;

				clocks = <&cmu_fsys0 CLK_GOUT_FSYS0_SCLK_USBDRD30_REF_CLK>;
				clock-names = "ref";

				interrupts = <GIC_SPI 213 IRQ_TYPE_LEVEL_HIGH>;

				phys = <&usbdrd30_phy 0>;
				phy-names = "usb2-phy";

				status = "disabled";
			};
		};

		usbdrd30_phy: phy@15500000 {
			compatible = "samsung,exynos8890-usbdrd-phy";
			reg = <0x15500000 0x100>;
			clocks = <&cmu_fsys0 CLK_GOUT_FSYS0_PHYCLK_USBDRD30_UDRD30_PHYCLOCK>,
				 <&oscclk>,
				 <&cmu_fsys0 CLK_GOUT_FSYS0_PHYCLK_USBDRD30_UDRD30_PIPE_PCLK>;
			clock-names = "phy", "ref", "pipe";
			#phy-cells = <1>;
			samsung,pmu-syscon = <&pmu_system_controller>;
			status = "disabled";
		};

		pinctrl_fsys1: pinctrl@15690000 {
			compatible = "samsung,exynos8890-pinctrl";
			reg = <0x15690000 0x1000>;
			clocks = <&cmu_fsys1 CLK_GOUT_FSYS1_PCLK_GPIO_FSYS1>;
			clock-names = "pclk";
			interrupts = <GIC_SPI 202 IRQ_TYPE_LEVEL_HIGH>;
		};

		cmu_fsys1: clock-controller@156e0000 {
			compatible = "samsung,exynos8890-cmu-fsys1";
			reg = <0x156e0000 0x8000>;
			#clock-cells = <1>;
			clocks = <&oscclk>,
				 <&cmu_top CLK_GOUT_TOP_ACLK_FSYS1_200>,
				 <&cmu_top CLK_GOUT_TOP_SCLK_FSYS1_MMC2>,
				 <&cmu_top CLK_GOUT_TOP_SCLK_FSYS1_UFSUNIPRO20>,
				 <&cmu_top CLK_GOUT_TOP_SCLK_FSYS1_UFSUNIPRO_CFG>,
				 <&cmu_top CLK_GOUT_TOP_SCLK_FSYS1_PCIE_PHY>,
				 <&cmu_top CLK_FOUT_PCIE_PLL>;
			clock-names = "oscclk", "200", "mmc2", "unipro20",
				      "unipro_cfg", "pcie_phy", "pcie_pll";
		};

		mmc: mmc@15740000 {
			compatible = "samsung,exynos8890-dw-mshc-smu",
				     "samsung,exynos7-dw-mshc-smu";
			reg = <0x15740000 0x2000>;

			assigned-clocks = <&cmu_top CLK_DOUT_TOP_SCLK_FSYS1_MMC2>;
			assigned-clock-rates = <800000000>;

			clocks = <&cmu_fsys1 CLK_GOUT_FSYS1_ACLK_MMC2>,
				 <&cmu_fsys1 CLK_GOUT_FSYS1_SCLK_MMC2>;
			clock-names = "biu", "ciu";

			fifo-depth = <64>;

			interrupts = <GIC_SPI 201 IRQ_TYPE_LEVEL_HIGH>;

			#address-cells = <1>;
			#size-cells = <0>;

			status = "disabled";
		};
	};

	timer {
		compatible = "arm,armv8-timer";
		/* Hypervisor Virtual Timer interrupt is not wired to GIC */
		interrupts = <GIC_PPI 13 (GIC_CPU_MASK_SIMPLE(8) | IRQ_TYPE_LEVEL_LOW)>,
			     <GIC_PPI 14 (GIC_CPU_MASK_SIMPLE(8) | IRQ_TYPE_LEVEL_LOW)>,
			     <GIC_PPI 11 (GIC_CPU_MASK_SIMPLE(8) | IRQ_TYPE_LEVEL_LOW)>,
			     <GIC_PPI 10 (GIC_CPU_MASK_SIMPLE(8) | IRQ_TYPE_LEVEL_LOW)>;
		/*
		 * Non-updatable, broken stock Samsung bootloader does not
		 * configure CNTFRQ_EL0
		 */
		clock-frequency = <26000000>;
	};
};

#include "exynos8890-pinctrl.dtsi"
#include "arm/samsung/exynos-syscon-restart.dtsi"
